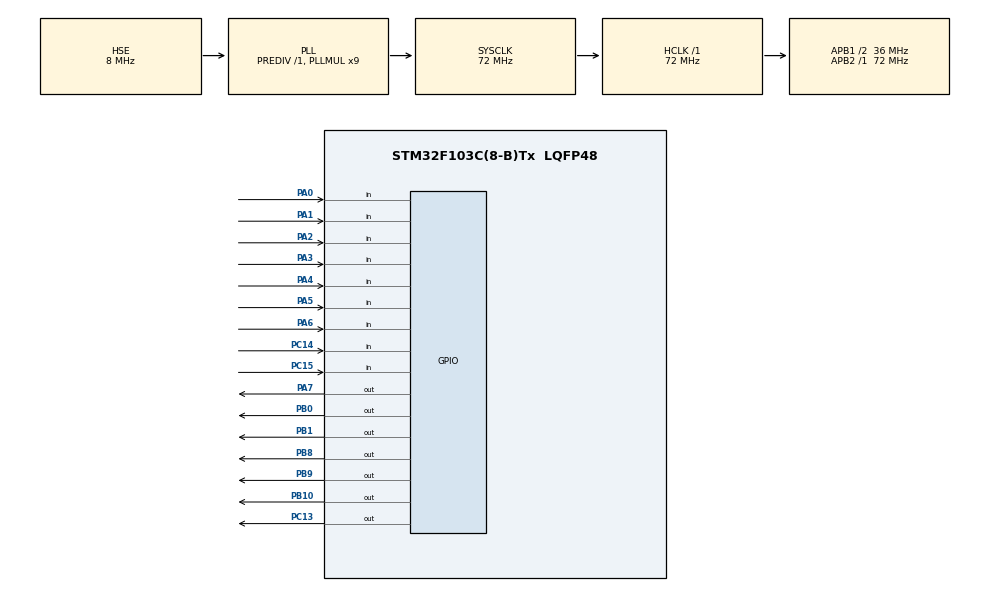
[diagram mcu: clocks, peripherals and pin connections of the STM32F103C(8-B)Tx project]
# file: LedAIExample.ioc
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FREERTOS.Queues01=BtnMsgQueue,8,uint8_t,0,Dynamic,NULL,NULL;KeyPadMsgQueue,16,uint32_t,0,Dynamic,NULL,NULL;CalcDisplayMsgQueue,34,uint16_t,0,Dynamic,NULL,NULL
FREERTOS.Tasks01=LedTask,24,128,vLedTask,As weak,NULL,Dynamic,NULL,NULL;BtnTask,24,128,vBtnTask,As weak,NULL,Dynamic,NULL,NULL;BtnProcessTask,25,128,vBtnProcessTask,As weak,NULL,Dynamic,NULL,NULL;OledTask,25,128,vOledTask,As weak,NULL,Dynamic,NULL,NULL;KeyPadTask,24,128,vKeyPadTask,As weak,NULL,Dynamic,NULL,NULL;CalcTask,24,128,vCalcTask,As weak,NULL,Dynamic,NULL,NULL
FREERTOS.configTOTAL_HEAP_SIZE=8192
Mcu.Family=STM32F1
Mcu.Name=STM32F103C(8-B)Tx
Mcu.Package=LQFP48
NVIC.PriorityGroup=NVIC_PRIORITYGROUP_4
PA0-WKUP.GPIO_PuPd=GPIO_PULLUP
PA0-WKUP.Signal=GPIO_Input
PA1.GPIO_PuPd=GPIO_PULLUP
PA1.Signal=GPIO_Input
PA13.Mode=Serial_Wire
PA13.Signal=SYS_JTMS-SWDIO
PA14.Mode=Serial_Wire
PA14.Signal=SYS_JTCK-SWCLK
PA2.GPIO_PuPd=GPIO_PULLUP
PA2.Signal=GPIO_Input
PA3.GPIO_PuPd=GPIO_PULLUP
PA3.Signal=GPIO_Input
PA4.GPIO_PuPd=GPIO_PULLUP
PA4.Signal=GPIO_Input
PA5.GPIO_PuPd=GPIO_PULLUP
PA5.Signal=GPIO_Input
PA6.GPIO_PuPd=GPIO_PULLUP
PA6.Signal=GPIO_Input
PA7.GPIO_ModeDefaultOutputPP=GPIO_MODE_OUTPUT_OD
PA7.GPIO_PuPd=GPIO_PULLUP
PA7.Signal=GPIO_Output
PB0.GPIO_ModeDefaultOutputPP=GPIO_MODE_OUTPUT_OD
PB0.GPIO_PuPd=GPIO_PULLUP
PB0.Signal=GPIO_Output
PB1.GPIO_ModeDefaultOutputPP=GPIO_MODE_OUTPUT_OD
PB1.GPIO_PuPd=GPIO_PULLUP
PB1.Signal=GPIO_Output
PB10.GPIO_ModeDefaultOutputPP=GPIO_MODE_OUTPUT_OD
PB10.GPIO_PuPd=GPIO_PULLUP
PB10.Signal=GPIO_Output
PB8.GPIO_PuPd=GPIO_PULLUP
PB8.GPIO_Speed=GPIO_SPEED_FREQ_HIGH
PB8.Signal=GPIO_Output
PB9.GPIO_PuPd=GPIO_PULLUP
PB9.GPIO_Speed=GPIO_SPEED_FREQ_HIGH
PB9.Signal=GPIO_Output
PC13-TAMPER-RTC.Signal=GPIO_Output
PC14-OSC32_IN.GPIO_PuPd=GPIO_PULLUP
PC14-OSC32_IN.Signal=GPIO_Input
PC15-OSC32_OUT.GPIO_PuPd=GPIO_PULLUP
PC15-OSC32_OUT.Signal=GPIO_Input
PD0-OSC_IN.Mode=HSE-External-Oscillator
PD0-OSC_IN.Signal=RCC_OSC_IN
PD1-OSC_OUT.Mode=HSE-External-Oscillator
PD1-OSC_OUT.Signal=RCC_OSC_OUT
ProjectManager.HeapSize=0x200
ProjectManager.StackSize=0x400
ProjectManager.TargetToolchain=MDK-ARM V5.32
RCC.AHBFreq_Value=72000000
RCC.APB1CLKDivider=RCC_HCLK_DIV2
RCC.APB1Freq_Value=36000000
RCC.APB1TimFreq_Value=72000000
RCC.APB2Freq_Value=72000000
RCC.APB2TimFreq_Value=72000000
RCC.HCLKFreq_Value=72000000
RCC.PLLMUL=RCC_PLL_MUL9
RCC.PLLSourceVirtual=RCC_PLLSOURCE_HSE
RCC.SYSCLKFreq_VALUE=72000000
RCC.SYSCLKSource=RCC_SYSCLKSOURCE_PLLCLK
RCC.USBFreq_Value=72000000
VP_FREERTOS_VS_CMSIS_V2.Mode=CMSIS_V2
board=custom

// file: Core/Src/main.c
/* USER CODE BEGIN Header */
/**
  ******************************************************************************
  * @file           : main.c
  * @brief          : Main program body
  ******************************************************************************
  * @attention
  *
  * Copyright (c) 2026 STMicroelectronics.
  * All rights reserved.
  *
  * This software is licensed under terms that can be found in the LICENSE file
  * in the root directory of this software component.
  * If no LICENSE file comes with this software, it is provided AS-IS.
  *
  ******************************************************************************
  */
/* USER CODE END Header */
#include "main.h"
#include "cmsis_os.h"

/* Definitions for LedTask */
osThreadId_t LedTaskHandle;
const osThreadAttr_t LedTask_attributes = {
  .name = "LedTask",
  .stack_size = 128 * 4,
  .priority = (osPriority_t) osPriorityNormal,
};
/* Definitions for BtnTask */
osThreadId_t BtnTaskHandle;
const osThreadAttr_t BtnTask_attributes = {
  .name = "BtnTask",
  .stack_size = 128 * 4,
  .priority = (osPriority_t) osPriorityNormal,
};
/* Definitions for BtnProcessTask */
osThreadId_t BtnProcessTaskHandle;
const osThreadAttr_t BtnProcessTask_attributes = {
  .name = "BtnProcessTask",
  .stack_size = 128 * 4,
  .priority = (osPriority_t) osPriorityNormal1,
};
/* Definitions for OledTask */
osThreadId_t OledTaskHandle;
const osThreadAttr_t OledTask_attributes = {
  .name = "OledTask",
  .stack_size = 128 * 4,
  .priority = (osPriority_t) osPriorityNormal1,
};
/* Definitions for KeyPadTask */
osThreadId_t KeyPadTaskHandle;
const osThreadAttr_t KeyPadTask_attributes = {
  .name = "KeyPadTask",
  .stack_size = 128 * 4,
  .priority = (osPriority_t) osPriorityNormal,
};
/* Definitions for CalcTask */
osThreadId_t CalcTaskHandle;
const osThreadAttr_t CalcTask_attributes = {
  .name = "CalcTask",
  .stack_size = 128 * 4,
  .priority = (osPriority_t) osPriorityNormal,
};
/* Definitions for BtnMsgQueue */
osMessageQueueId_t BtnMsgQueueHandle;
const osMessageQueueAttr_t BtnMsgQueue_attributes = {
  .name = "BtnMsgQueue"
};
/* Definitions for KeyPadMsgQueue */
osMessageQueueId_t KeyPadMsgQueueHandle;
const osMessageQueueAttr_t KeyPadMsgQueue_attributes = {
  .name = "KeyPadMsgQueue"
};
/* Definitions for CalcDisplayMsgQueue */
osMessageQueueId_t CalcDisplayMsgQueueHandle;
const osMessageQueueAttr_t CalcDisplayMsgQueue_attributes = {
  .name = "CalcDisplayMsgQueue"
};
/* USER CODE BEGIN PV */
 osMessageQueueId_t BtnMsgQueueHandle;
/* USER CODE END PV */

void SystemClock_Config(void);
static void MX_GPIO_Init(void);
void vLedTask(void *argument);
void vBtnTask(void *argument);
void vBtnProcessTask(void *argument);
void vOledTask(void *argument);
void vKeyPadTask(void *argument);
void vCalcTask(void *argument);

int main(void)
{

  /* MCU Configuration--------------------------------------------------------*/

  /* Reset of all peripherals, Initializes the Flash interface and the Systick. */
  HAL_Init();

  /* Configure the system clock */
  SystemClock_Config();

  /* Initialize all configured peripherals */
  MX_GPIO_Init();

  /* Init scheduler */
  osKernelInitialize();

  /* Create the queue(s) */
  /* creation of BtnMsgQueue */
  BtnMsgQueueHandle = osMessageQueueNew (8, sizeof(uint8_t), &BtnMsgQueue_attributes);

  /* creation of KeyPadMsgQueue */
  KeyPadMsgQueueHandle = osMessageQueueNew (16, sizeof(uint32_t), &KeyPadMsgQueue_attributes);

  /* creation of CalcDisplayMsgQueue */
  CalcDisplayMsgQueueHandle = osMessageQueueNew (34, sizeof(uint16_t), &CalcDisplayMsgQueue_attributes);

  /* Create the thread(s) */
  /* creation of LedTask */
  LedTaskHandle = osThreadNew(vLedTask, NULL, &LedTask_attributes);

  /* creation of BtnTask */
  BtnTaskHandle = osThreadNew(vBtnTask, NULL, &BtnTask_attributes);

  /* creation of BtnProcessTask */
  BtnProcessTaskHandle = osThreadNew(vBtnProcessTask, NULL, &BtnProcessTask_attributes);

  /* creation of OledTask */
  OledTaskHandle = osThreadNew(vOledTask, NULL, &OledTask_attributes);

  /* creation of KeyPadTask */
  KeyPadTaskHandle = osThreadNew(vKeyPadTask, NULL, &KeyPadTask_attributes);

  /* creation of CalcTask */
  CalcTaskHandle = osThreadNew(vCalcTask, NULL, &CalcTask_attributes);

  /* Start scheduler */
  osKernelStart();

  /* We should never get here as control is now taken by the scheduler */

  /* Infinite loop */
  while (1)
  {

  }
}

void SystemClock_Config(void)
{
  RCC_OscInitTypeDef RCC_OscInitStruct = {0};
  RCC_ClkInitTypeDef RCC_ClkInitStruct = {0};

  /** Initializes the RCC Oscillators according to the specified parameters
  * in the RCC_OscInitTypeDef structure.
  */
  RCC_OscInitStruct.OscillatorType = RCC_OSCILLATORTYPE_HSE;
  RCC_OscInitStruct.HSEState = RCC_HSE_ON;
  RCC_OscInitStruct.HSEPredivValue = RCC_HSE_PREDIV_DIV1;
  RCC_OscInitStruct.HSIState = RCC_HSI_ON;
  RCC_OscInitStruct.PLL.PLLState = RCC_PLL_ON;
  RCC_OscInitStruct.PLL.PLLSource = RCC_PLLSOURCE_HSE;
  RCC_OscInitStruct.PLL.PLLMUL = RCC_PLL_MUL9;
  if (HAL_RCC_OscConfig(&RCC_OscInitStruct) != HAL_OK)
  {
    Error_Handler();
  }

  /** Initializes the CPU, AHB and APB buses clocks
  */
  RCC_ClkInitStruct.ClockType = RCC_CLOCKTYPE_HCLK|RCC_CLOCKTYPE_SYSCLK
                              |RCC_CLOCKTYPE_PCLK1|RCC_CLOCKTYPE_PCLK2;
  RCC_ClkInitStruct.SYSCLKSource = RCC_SYSCLKSOURCE_PLLCLK;
  RCC_ClkInitStruct.AHBCLKDivider = RCC_SYSCLK_DIV1;
  RCC_ClkInitStruct.APB1CLKDivider = RCC_HCLK_DIV2;
  RCC_ClkInitStruct.APB2CLKDivider = RCC_HCLK_DIV1;

  if (HAL_RCC_ClockConfig(&RCC_ClkInitStruct, FLASH_LATENCY_2) != HAL_OK)
  {
    Error_Handler();
  }
}

static void MX_GPIO_Init(void)
{
  GPIO_InitTypeDef GPIO_InitStruct = {0};

  /* GPIO Ports Clock Enable */
  __HAL_RCC_GPIOC_CLK_ENABLE();
  __HAL_RCC_GPIOD_CLK_ENABLE();
  __HAL_RCC_GPIOA_CLK_ENABLE();
  __HAL_RCC_GPIOB_CLK_ENABLE();

  /*Configure GPIO pin Output Level */
  HAL_GPIO_WritePin(GPIOC, GPIO_PIN_13, GPIO_PIN_RESET);

  /*Configure GPIO pin Output Level */
  HAL_GPIO_WritePin(GPIOA, GPIO_PIN_7, GPIO_PIN_RESET);

  /*Configure GPIO pin Output Level */
  HAL_GPIO_WritePin(GPIOB, GPIO_PIN_0|GPIO_PIN_1|GPIO_PIN_10|GPIO_PIN_8
                          |GPIO_PIN_9, GPIO_PIN_RESET);

  /*Configure GPIO pin : PC13 */
  GPIO_InitStruct.Pin = GPIO_PIN_13;
  GPIO_InitStruct.Mode = GPIO_MODE_OUTPUT_PP;
  GPIO_InitStruct.Pull = GPIO_NOPULL;
  GPIO_InitStruct.Speed = GPIO_SPEED_FREQ_LOW;
  HAL_GPIO_Init(GPIOC, &GPIO_InitStruct);

  /*Configure GPIO pins : PC14 PC15 */
  GPIO_InitStruct.Pin = GPIO_PIN_14|GPIO_PIN_15;
  GPIO_InitStruct.Mode = GPIO_MODE_INPUT;
  GPIO_InitStruct.Pull = GPIO_PULLUP;
  HAL_GPIO_Init(GPIOC, &GPIO_InitStruct);

  /*Configure GPIO pins : PA0 PA1 PA2 PA3
                           PA4 PA5 PA6 */
  GPIO_InitStruct.Pin = GPIO_PIN_0|GPIO_PIN_1|GPIO_PIN_2|GPIO_PIN_3
                          |GPIO_PIN_4|GPIO_PIN_5|GPIO_PIN_6;
  GPIO_InitStruct.Mode = GPIO_MODE_INPUT;
  GPIO_InitStruct.Pull = GPIO_PULLUP;
  HAL_GPIO_Init(GPIOA, &GPIO_InitStruct);

  /*Configure GPIO pin : PA7 */
  GPIO_InitStruct.Pin = GPIO_PIN_7;
  GPIO_InitStruct.Mode = GPIO_MODE_OUTPUT_OD;
  GPIO_InitStruct.Pull = GPIO_PULLUP;
  GPIO_InitStruct.Speed = GPIO_SPEED_FREQ_LOW;
  HAL_GPIO_Init(GPIOA, &GPIO_InitStruct);

  /*Configure GPIO pins : PB0 PB1 PB10 */
  GPIO_InitStruct.Pin = GPIO_PIN_0|GPIO_PIN_1|GPIO_PIN_10;
  GPIO_InitStruct.Mode = GPIO_MODE_OUTPUT_OD;
  GPIO_InitStruct.Pull = GPIO_PULLUP;
  GPIO_InitStruct.Speed = GPIO_SPEED_FREQ_LOW;
  HAL_GPIO_Init(GPIOB, &GPIO_InitStruct);

  /*Configure GPIO pins : PB8 PB9 */
  GPIO_InitStruct.Pin = GPIO_PIN_8|GPIO_PIN_9;
  GPIO_InitStruct.Mode = GPIO_MODE_OUTPUT_PP;
  GPIO_InitStruct.Pull = GPIO_PULLUP;
  GPIO_InitStruct.Speed = GPIO_SPEED_FREQ_HIGH;
  HAL_GPIO_Init(GPIOB, &GPIO_InitStruct);

}

__weak void vLedTask(void *argument)
{
  /* USER CODE BEGIN 5 */
  /* Infinite loop */
  for(;;)
  {
    //PC13翻转
    HAL_GPIO_TogglePin(GPIOC,GPIO_PIN_13);
    osDelay(500);
  }
  /* USER CODE END 5 */
}

__weak void vBtnTask(void *argument)
{
  for(;;)
  {
    osDelay(1);
  }
}

__weak void vBtnProcessTask(void *argument)
{
  for(;;)
  {
    osDelay(1);
  }
}

__weak void vOledTask(void *argument)
{
  for(;;)
  {
    osDelay(1);
  }
}

__weak void vKeyPadTask(void *argument)
{
  for(;;)
  {
    osDelay(1);
  }
}

__weak void vCalcTask(void *argument)
{
  for(;;)
  {
    osDelay(1);
  }
}

void Error_Handler(void)
{
  __disable_irq();
  while (1)
  {
  }
}
